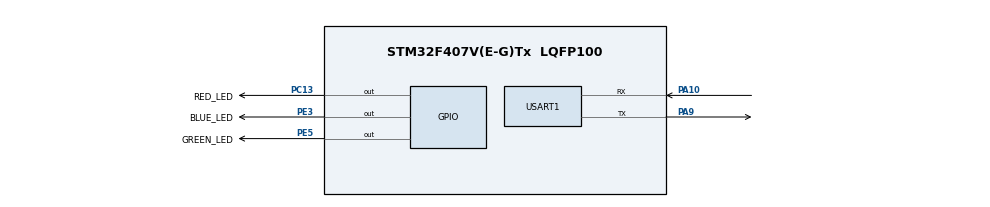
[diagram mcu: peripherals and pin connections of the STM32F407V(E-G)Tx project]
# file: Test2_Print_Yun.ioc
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Mcu.Family=STM32F4
PC15-OSC32_OUT.Mode=LSE-External-Oscillator
PH0-OSC_IN.Signal=RCC_OSC_IN
RCC.CortexFreq_Value=16000000
PA10.Mode=Asynchronous
PC13-ANTI_TAMP.GPIO_Label=RED_LED
PC14-OSC32_IN.Signal=RCC_OSC32_IN
PC13-ANTI_TAMP.PinState=GPIO_PIN_SET
ProjectManager.StackSize=0x400
PA13.Signal=SYS_JTMS-SWDIO
PA9.Mode=Asynchronous
ProjectManager.TargetToolchain=STM32CubeIDE
PA9.Signal=USART1_TX
PE5.Signal=GPIO_Output
PC15-OSC32_OUT.Signal=RCC_OSC32_OUT
RCC.AHBFreq_Value=16000000
PH0-OSC_IN.Mode=HSE-External-Oscillator
PE3.PinState=GPIO_PIN_SET
RCC.HSE_VALUE=25000000
board=custom
PC13-ANTI_TAMP.Signal=GPIO_Output
RCC.VCOOutputFreq_Value=192000000
RCC.APB2Freq_Value=16000000
PC14-OSC32_IN.Mode=LSE-External-Oscillator
PA14.Mode=Serial_Wire
PE5.PinState=GPIO_PIN_SET
PH1-OSC_OUT.Signal=RCC_OSC_OUT
PA13.Mode=Serial_Wire
Mcu.Name=STM32F407V(E-G)Tx
PH1-OSC_OUT.Mode=HSE-External-Oscillator
RCC.SYSCLKFreq_VALUE=16000000
Mcu.Package=LQFP100
PE5.GPIO_Label=GREEN_LED
USART1.VirtualMode=VM_ASYNC
PA10.Signal=USART1_RX
PA14.Signal=SYS_JTCK-SWCLK
ProjectManager.HeapSize=0x200
RCC.HSI_VALUE=16000000
NVIC.PriorityGroup=NVIC_PRIORITYGROUP_4
PE3.Signal=GPIO_Output
PE3.GPIO_Label=BLUE_LED
NVIC.USART1_IRQn=true\:0\:0\:false\:false\:true\:true\:true
RCC.APB1Freq_Value=16000000

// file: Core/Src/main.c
/* USER CODE BEGIN Header */
/**
  ******************************************************************************
  * @file           : main.c
  * @brief          : Main program body
  ******************************************************************************
  * @attention
  *
  * <h2><center>&copy; Copyright (c) 2021 STMicroelectronics.
  * All rights reserved.</center></h2>
  *
  * This software component is licensed by ST under BSD 3-Clause license,
  * the "License"; You may not use this file except in compliance with the
  * License. You may obtain a copy of the License at:
  *                        opensource.org/licenses/BSD-3-Clause
  *
  ******************************************************************************
  */
/* USER CODE END Header */
#include "main.h"
#include "usart.h"
#include "gpio.h"

void SystemClock_Config(void);

int main(void)
{

  /* MCU Configuration--------------------------------------------------------*/

  /* Reset of all peripherals, Initializes the Flash interface and the Systick. */

  LL_APB2_GRP1_EnableClock(LL_APB2_GRP1_PERIPH_SYSCFG);
  LL_APB1_GRP1_EnableClock(LL_APB1_GRP1_PERIPH_PWR);

  NVIC_SetPriorityGrouping(NVIC_PRIORITYGROUP_4);

  /* System interrupt init*/

  /* Configure the system clock */
  SystemClock_Config();

  /* Initialize all configured peripherals */
  MX_GPIO_Init();
  MX_USART1_UART_Init();
  /* USER CODE BEGIN 2 */
  printf("Hello World!\n");
  DEBUG_PRINT(WORD_OK, "初始化GPIO和USART成功");
  /* USER CODE END 2 */

  /* Infinite loop */
  while (1)
  {

  }
}

void SystemClock_Config(void)
{
  LL_FLASH_SetLatency(LL_FLASH_LATENCY_0);
  while(LL_FLASH_GetLatency()!= LL_FLASH_LATENCY_0)
  {
  }
  LL_PWR_SetRegulVoltageScaling(LL_PWR_REGU_VOLTAGE_SCALE1);
  LL_RCC_HSI_SetCalibTrimming(16);
  LL_RCC_HSI_Enable();

   /* Wait till HSI is ready */
  while(LL_RCC_HSI_IsReady() != 1)
  {

  }
  LL_RCC_SetAHBPrescaler(LL_RCC_SYSCLK_DIV_1);
  LL_RCC_SetAPB1Prescaler(LL_RCC_APB1_DIV_1);
  LL_RCC_SetAPB2Prescaler(LL_RCC_APB2_DIV_1);
  LL_RCC_SetSysClkSource(LL_RCC_SYS_CLKSOURCE_HSI);

   /* Wait till System clock is ready */
  while(LL_RCC_GetSysClkSource() != LL_RCC_SYS_CLKSOURCE_STATUS_HSI)
  {

  }
  LL_Init1msTick(16000000);
  LL_SetSystemCoreClock(16000000);
}

void Error_Handler(void)
{
  __disable_irq();
  while (1)
  {
  }
}

/************************ (C) COPYRIGHT STMicroelectronics *****END OF FILE****/
